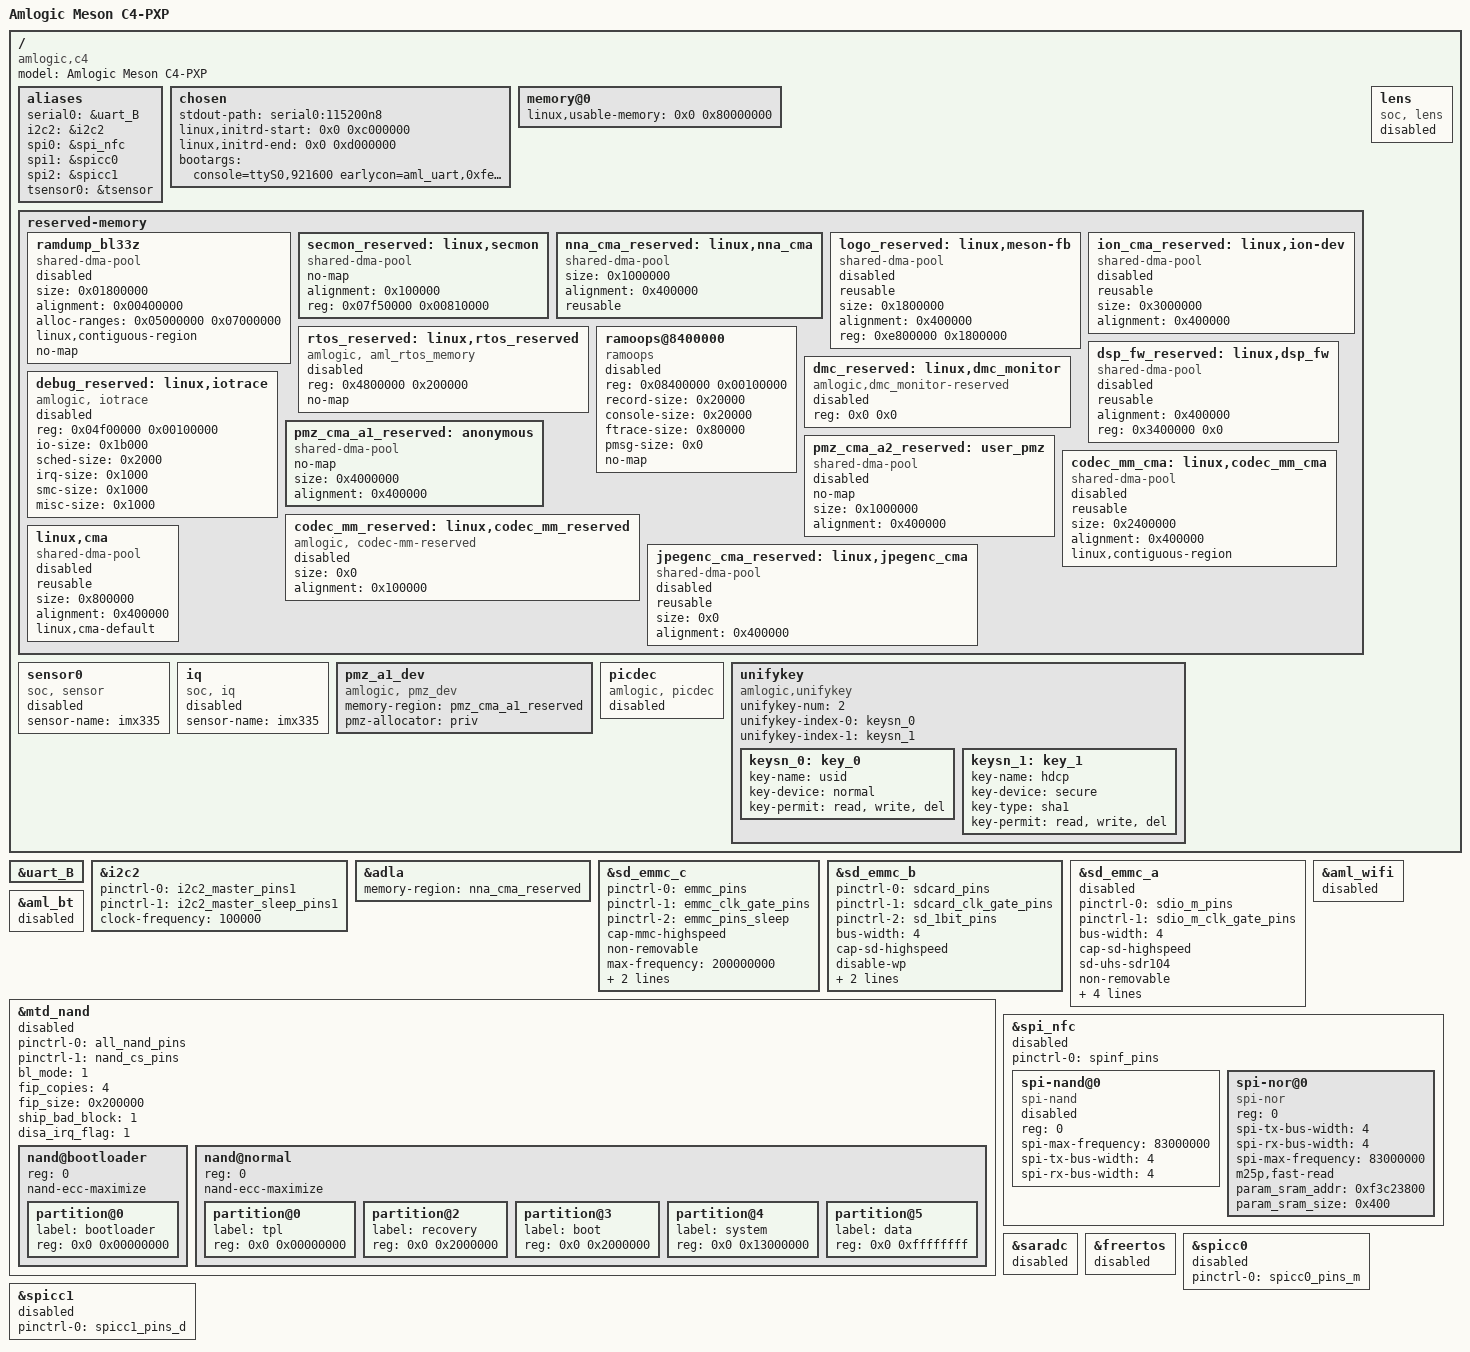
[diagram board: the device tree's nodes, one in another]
// SPDX-License-Identifier: (GPL-2.0+ OR MIT)
/*
 * Copyright (c) 2019 Amlogic, Inc. All rights reserved.
 */

/dts-v1/;

#include "meson-c4.dtsi"
#include "mesonc4_audio.dtsi"
/ {
	compatible = "amlogic,c4";
	model = "Amlogic Meson C4-PXP";

	aliases {
		serial0 = &uart_B;
		i2c2 = &i2c2;
		spi0 = &spi_nfc;
		spi1 = &spicc0;
		spi2 = &spicc1;
		tsensor0 = &tsensor;
	};

	chosen {
		stdout-path = "serial0:115200n8";
		linux,initrd-start = <0x0 0xc000000>;
		linux,initrd-end = <0x0   0xd000000>;
		bootargs = "console=ttyS0,921600  earlycon=aml_uart,0xfe07a000
			debug initcall_debug=0 loglevel=7
			module_blacklist=amlogic_wireless clk_ignore_unused";
	};

	memory@0 {
		device_type = "memory";
		linux,usable-memory = <0x0 0x80000000>;
	};

	reserved-memory {
		#address-cells = <1>;
		#size-cells = <1>;
		ranges;

		ramdump_bl33z {
			compatible = "shared-dma-pool";
			size = <0x01800000>;
			alignment = <0x00400000>;
			alloc-ranges = <0x05000000 0x07000000>;
			linux,contiguous-region;
			no-map;
			status = "disabled";
		};

		secmon_reserved:linux,secmon {
			compatible = "shared-dma-pool";
			no-map;
			alignment = <0x100000>;
			reg = <0x07f50000 0x00810000>;
		};
		nna_cma_reserved: linux,nna_cma {
			compatible = "shared-dma-pool";
			//alloc-ranges = <0x70000000 0x18000000>;
			size = <0x1000000>;
			alignment = <0x400000>;
			reusable;
			//no-map;
			status = "okay";
		};

		logo_reserved:linux,meson-fb {
			compatible = "shared-dma-pool";
			reusable;
			/* keep sync with fb */
			/* fox example:logo_addr = "0x3f800000"*/
			size = <0x1800000>;
			alignment = <0x400000>;
			reg = <0xe800000 0x1800000>;
				status = "disabled";
		};

		ion_cma_reserved:linux,ion-dev {
			compatible = "shared-dma-pool";
			reusable;
			size = <0x3000000>;
			alignment = <0x400000>;
				status = "disabled";
		};

		rtos_reserved:linux,rtos_reserved {
			compatible = "amlogic, aml_rtos_memory";
			status = "disabled";
			reg = <0x4800000 0x200000>;
			no-map;
		};

		dsp_fw_reserved:linux,dsp_fw {
			compatible = "shared-dma-pool";
			reusable;
			alignment = <0x400000>;
			reg = <0x3400000 0x0>;
			status = "disabled";
		};

		ramoops@8400000 {
			compatible = "ramoops";
			status = "disabled";
			reg = <0x08400000 0x00100000>;
			record-size = <0x20000>;
			console-size = <0x20000>;
			ftrace-size = <0x80000>;
			pmsg-size = <0x0>;
			no-map;
		};

		dmc_reserved:linux,dmc_monitor {
			compatible = "amlogic,dmc_monitor-reserved";
			reg = <0x0 0x0>;
				status = "disabled";
		};

		debug_reserved:linux,iotrace {
			compatible = "amlogic, iotrace";
			reg = <0x04f00000 0x00100000>;
			io-size = <0x1b000>;
			sched-size = <0x2000>;
			irq-size = <0x1000>;
			smc-size = <0x1000>;
			misc-size = <0x1000>;
			status = "disabled";
		};

		pmz_cma_a1_reserved:anonymous {
			compatible = "shared-dma-pool";
			//reusable;
			no-map;
			size = <0x4000000>;
			alignment = <0x400000>;
			status = "okay";
		};

		pmz_cma_a2_reserved:user_pmz {
			compatible = "shared-dma-pool";
			//reusable;
			no-map;
			size = <0x1000000>;
			alignment = <0x400000>;
			status = "disabled";
		};

		codec_mm_cma:linux,codec_mm_cma {
			compatible = "shared-dma-pool";
			reusable;
			/* ion_codec_mm max can alloc size 80M*/
			size = <0x2400000>;
			alignment = <0x400000>;
			linux,contiguous-region;
			status = "disabled";
		};
		/* codec shared reserved */
		codec_mm_reserved:linux,codec_mm_reserved {
			compatible = "amlogic, codec-mm-reserved";
			size = <0x0>;
			alignment = <0x100000>;
			//no-map;
			status = "disabled";
		};
		jpegenc_cma_reserved:linux,jpegenc_cma {
			compatible = "shared-dma-pool";
			reusable;
			size = <0x0>;
			alignment = <0x400000>;
			status = "disabled";
		};

		/* global autoconfigured region for contiguous allocations */
		linux,cma {
			compatible = "shared-dma-pool";
			reusable;
			size = <0x800000>;
			alignment = <0x400000>;
			linux,cma-default;
			status = "disabled";
		};
	};

	sensor0: sensor0 {
		compatible = "soc, sensor";
		status = "disabled";
		sensor-name = "imx335"; /*imx290;os08a10;imx227*/
		pinctrl-names= "default";
		//clocks = <&clkc CLKID_GP_PLL_MCLK1_GATE>;
		clock-names = "mclk_0";
		//reset = <&gpio GPIOM_11 GPIO_ACTIVE_HIGH>;
		//pwdn = <&gpio GPIOM_10 GPIO_ACTIVE_HIGH>;
	};

	iq: iq {
		compatible = "soc, iq";
		status = "disabled";
		sensor-name = "imx335"; /*imx290;os08a10;imx227*/
	};

	lens: lens {
		compatible = "soc, lens";
		status = "disabled";
	};

	pmz_a1_dev {
		compatible = "amlogic, pmz_dev";
		memory-region = <&pmz_cma_a1_reserved>;
		pmz-allocator = "priv";
	};
	picdec {
		compatible = "amlogic, picdec";
		status = "disabled";
	};

	/* Audio Related end */
	/* to check
	 *wifivbat_power: regulator-wifivbat {
	 *	compatible = "regulator-fixed";
	 *	regulator-name = "WIFIVBAT_POWER";
	 *	vin-supply = <&vddao3v3_reg>;
	 *	regulator-min-microvolt = <3300000>;
	 *	regulator-max-microvolt = <3300000>;
	 *	gpio = <&gpio GPIOD_13 GPIO_ACTIVE_HIGH>;
	 *	enable-active-high;
	 *	regulator-boot-on;
	 *	regulator-always-on;
	 *};

	 *vddio_wf: regulator_wfio {
	 *	compatible = "regulator-fixed";
	 *	regulator-name = "VDDIO_WF";
	 *	vin-supply = <&vddao1v8_reg>;
	 *	regulator-min-microvolt = <1800000>;
	 *	regulator-max-microvolt = <1800000>;
	 *	regulator-boot-on;
	 *	regulator-always-on;
	 *};
	 */

	unifykey{
		compatible = "amlogic,unifykey";
		status = "okay";
		unifykey-num = <2>;
		unifykey-index-0 = <&keysn_0>;
		unifykey-index-1 = <&keysn_1>;

		keysn_0: key_0{
			key-name = "usid";
			key-device = "normal";
			key-permit = "read","write","del";
		};
		keysn_1:key_1{
			key-name = "hdcp";
			key-device = "secure";
			key-type = "sha1";
			key-permit = "read","write","del";
		};
	};//End unifykey
};

&uart_B {
	status = "okay";
};

&i2c2 {
	status = "okay";
	pinctrl-names = "default", "sleep";
	pinctrl-0 = <&i2c2_master_pins1>;
	pinctrl-1 = <&i2c2_master_sleep_pins1>;
	clock-frequency = <100000>; /* default 100k */
};

&adla {
	status = "okay";
	memory-region = <&nna_cma_reserved>;
};

&sd_emmc_c {
	status = "okay";
	pinctrl-0 = <&emmc_pins>;
	pinctrl-1 = <&emmc_clk_gate_pins>;
	pinctrl-2 = <&emmc_pins_sleep>;
	pinctrl-names = "default", "clk-gate", "sleep";
	cap-mmc-highspeed;
	non-removable;
	//mmc-run-pxp;
	//mmc-ddr-1_8v;
	//mmc-hs200-1_8v;
	//mmc-hs400-1_8v;
	max-frequency = <200000000>;
	disable-wp;
	bus-width = <8>;
};

&sd_emmc_b {
	status = "okay";
	pinctrl-0 = <&sdcard_pins>;
	pinctrl-1 = <&sdcard_clk_gate_pins>;
	pinctrl-2 = <&sd_1bit_pins>;
	pinctrl-names = "sd_default",
			"clk-gate",
			"sd_1bit_pins";
	bus-width = <4>;
	cap-sd-highspeed;
	//sd-uhs-sdr104;
	disable-wp;
	//mmc-run-pxp;
	max-frequency = <200000000>;
	cd-gpios = <&gpio GPIOC_6 GPIO_ACTIVE_HIGH>;
	//vmmc-supply = <&sdcard_power>;
	//vqmmc-supply = <&vddio_card>;
};

&sd_emmc_a {
	status = "disabled";
	pinctrl-0 = <&sdio_m_pins>;
	pinctrl-1 = <&sdio_m_clk_gate_pins>;
	pinctrl-names = "default", "clk-gate";
	bus-width = <4>;
	cap-sd-highspeed;
	sd-uhs-sdr104;
	non-removable;
	max-frequency = <200000000>;
	disable-wp;
	cap-sdio-irq;
	keep-power-in-suspend;
};

&aml_wifi {
	status = "disabled";
};

&aml_bt {
	status = "disabled";
};

&mtd_nand {
	status = "disabled";
	#address-cells = <1>;
	#size-cells = <0>;

	pinctrl-names = "nand_norb_mod","nand_cs_only";
	pinctrl-0 = <&all_nand_pins>;
	pinctrl-1 = <&nand_cs_pins>;
	bl_mode = <1>;
	fip_copies = <4>;
	fip_size = <0x200000>;
	ship_bad_block = <1>;
	disa_irq_flag = <1>;
	nand@bootloader {
		reg = <0>;
		#address-cells = <1>;
		#size-cells = <1>;
		nand-ecc-maximize;
		partition@0 {
			label = "bootloader";
			reg = <0x0 0x00000000>;
		};
	};
	nand@normal {
		reg = <0>;
		#address-cells = <1>;
		#size-cells = <1>;
		nand-ecc-maximize;

		partition@0 {
			label = "tpl";
			reg = <0x0 0x00000000>;
		};
		partition@2 {
			label = "recovery";
			reg = <0x0 0x2000000>;
		};
		partition@3 {
			label = "boot";
			reg = <0x0 0x2000000>;
		};
		partition@4 {
			label = "system";
			reg = <0x0 0x13000000>;
		};
		partition@5 {
			label = "data";
			reg = <0x0 0xffffffff>;
		};
	};
};

&spi_nfc {
	status = "disabled";
	pinctrl-names = "default";
	pinctrl-0 = <&spinf_pins>;
	spi-nand@0 {
		compatible = "spi-nand";
		status = "disabled";
		reg = <0>;
		spi-max-frequency = <83000000>;
		spi-tx-bus-width = <4>;
		spi-rx-bus-width = <4>;
	};
	spi-nor@0 {
		compatible = "spi-nor";
		status = "okay";
		reg = <0>;
		spi-tx-bus-width = <4>;
		spi-rx-bus-width = <4>;
		spi-max-frequency = <83000000>;
		m25p,fast-read;
		/* partition info sram addr */
		param_sram_addr = <0xf3c23800>;
		param_sram_size = <0x400>;
	};
};

&saradc {
	status = "disabled";
};

&freertos {
	status = "disabled";
};

&spicc0 {
	status = "disabled";
	pinctrl-names = "default";
	pinctrl-0 = <&spicc0_pins_m>;
};

&spicc1 {
	status = "disabled";
	pinctrl-names = "default";
	pinctrl-0 = <&spicc1_pins_d>;
};
